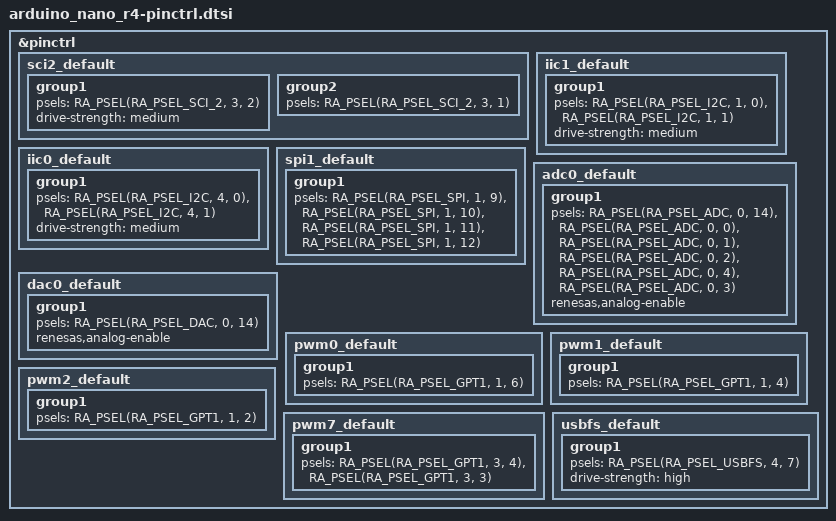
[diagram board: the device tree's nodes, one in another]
/*
 * SPDX-License-Identifier: Apache-2.0
 */

&pinctrl {
	sci2_default: sci2_default {
		group1 {
			/* tx */
			psels = <RA_PSEL(RA_PSEL_SCI_2, 3, 2)>;
			drive-strength = "medium";
		};

		group2 {
			/* rx */
			psels = <RA_PSEL(RA_PSEL_SCI_2, 3, 1)>;
		};
	};

	iic1_default: iic1_default {
		group1 {
			/* SCL1 SDA1 -- A5/A4 */
			psels = <RA_PSEL(RA_PSEL_I2C, 1, 0)>,
				<RA_PSEL(RA_PSEL_I2C, 1, 1)>;
			drive-strength = "medium";
		};
	};

	iic0_default: iic0_default {
		group1 {
			/* SCL0 SDA0 -- Qwiic connector */
			psels = <RA_PSEL(RA_PSEL_I2C, 4, 0)>,
				<RA_PSEL(RA_PSEL_I2C, 4, 1)>;
			drive-strength = "medium";
		};
	};

	spi1_default: spi1_default {
		group1 {
			/* MOSI MISO RSPCK SSL -- D11 D12 D13 D10 */
			psels = <RA_PSEL(RA_PSEL_SPI, 1, 9)>,
				<RA_PSEL(RA_PSEL_SPI, 1, 10)>,
				<RA_PSEL(RA_PSEL_SPI, 1, 11)>,
				<RA_PSEL(RA_PSEL_SPI, 1, 12)>;
		};
	};

	adc0_default: adc0_default {
		group1 {
			/* A0(DAC-shared) A1 A2 A3 A6 A7 */
			psels = <RA_PSEL(RA_PSEL_ADC, 0, 14)>,
				<RA_PSEL(RA_PSEL_ADC, 0, 0)>,
				<RA_PSEL(RA_PSEL_ADC, 0, 1)>,
				<RA_PSEL(RA_PSEL_ADC, 0, 2)>,
				<RA_PSEL(RA_PSEL_ADC, 0, 4)>,
				<RA_PSEL(RA_PSEL_ADC, 0, 3)>;
			renesas,analog-enable;
		};
	};

	dac0_default: dac0_default {
		group1 {
			/* A0 -- shares its pin with adc0 channel 9, mutually exclusive at runtime */
			psels = <RA_PSEL(RA_PSEL_DAC, 0, 14)>;
			renesas,analog-enable;
		};
	};

	pwm0_default: pwm0_default {
		group1 {
			/* GTIOC0B -- D6 */
			psels = <RA_PSEL(RA_PSEL_GPT1, 1, 6)>;
		};
	};

	pwm1_default: pwm1_default {
		group1 {
			/* GTIOC1B -- D3 (GTIOC1A/D11 not wired: shares its pin with spi1 MOSI) */
			psels = <RA_PSEL(RA_PSEL_GPT1, 1, 4)>;
		};
	};

	pwm2_default: pwm2_default {
		group1 {
			/* GTIOC2B -- D5 */
			psels = <RA_PSEL(RA_PSEL_GPT1, 1, 2)>;
		};
	};

	pwm7_default: pwm7_default {
		group1 {
			/* GTIOC7A GTIOC7B -- D8 D9 */
			psels = <RA_PSEL(RA_PSEL_GPT1, 3, 4)>,
				<RA_PSEL(RA_PSEL_GPT1, 3, 3)>;
		};
	};

	usbfs_default: usbfs_default {
		group1 {
			/* USB_VBUS */
			psels = <RA_PSEL(RA_PSEL_USBFS, 4, 7)>;
			drive-strength = "high";
		};
	};
};
